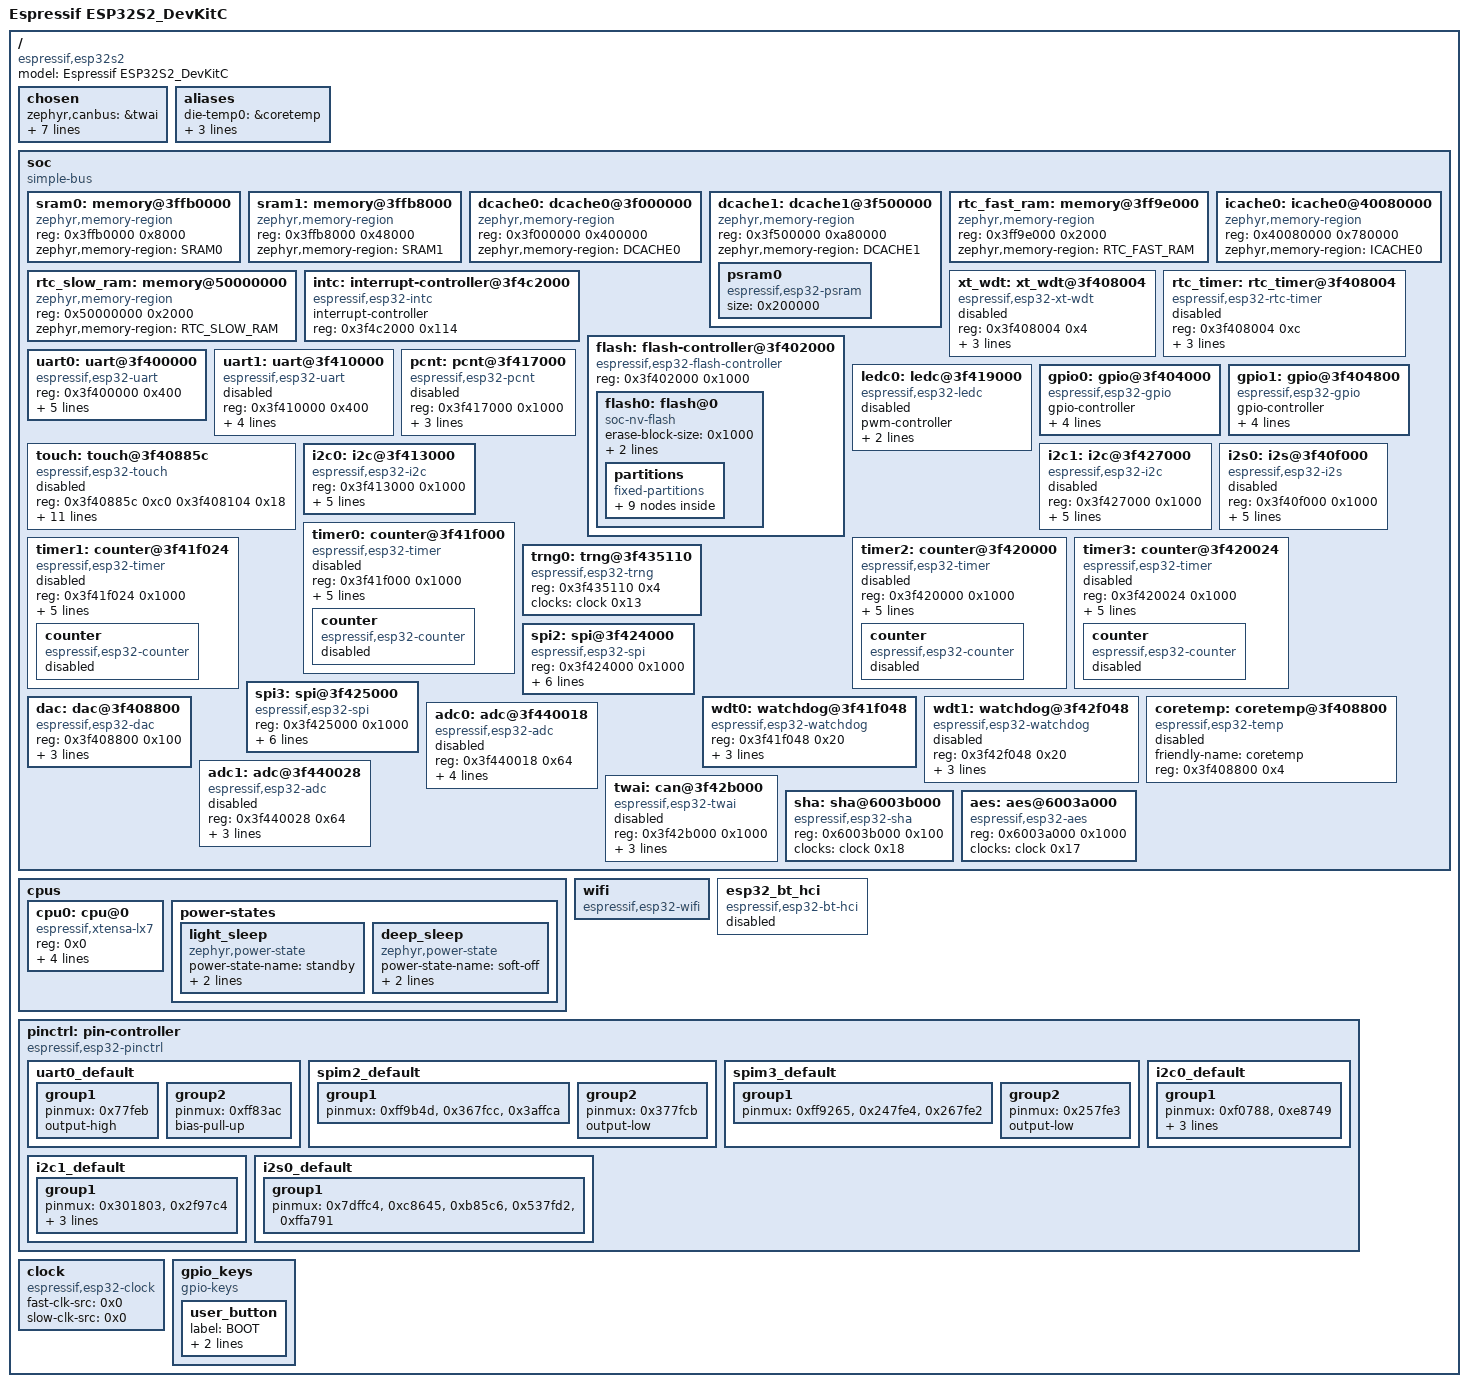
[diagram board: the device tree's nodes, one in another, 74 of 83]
/dts-v1/;

/* node '/' defined in zephyr/dts/common/skeleton.dtsi:9 */
/ {
	#address-cells = < 0x1 >;            /* in zephyr/dts/xtensa/espressif/esp32s2/esp32s2_common.dtsi:17 */
	#size-cells = < 0x1 >;               /* in zephyr/dts/xtensa/espressif/esp32s2/esp32s2_common.dtsi:18 */
	model = "Espressif ESP32S2_DevKitC"; /* in zephyr/boards/espressif/esp32s2_devkitc/esp32s2_devkitc.dts:16 */
	compatible = "espressif,esp32s2";    /* in zephyr/boards/espressif/esp32s2_devkitc/esp32s2_devkitc.dts:17 */

	/* node '/chosen' defined in zephyr/dts/common/skeleton.dtsi:13 */
	chosen {
		zephyr,canbus = &twai;                    /* in zephyr/dts/xtensa/espressif/esp32s2/esp32s2_common.dtsi:25 */
		zephyr,entropy = &trng0;                  /* in zephyr/dts/xtensa/espressif/esp32s2/esp32s2_common.dtsi:26 */
		zephyr,flash-controller = &flash;         /* in zephyr/dts/xtensa/espressif/esp32s2/esp32s2_common.dtsi:27 */
		zephyr,sram = &sram1;                     /* in zephyr/boards/espressif/esp32s2_devkitc/esp32s2_devkitc.dts:26 */
		zephyr,console = &uart0;                  /* in zephyr/boards/espressif/esp32s2_devkitc/esp32s2_devkitc.dts:27 */
		zephyr,shell-uart = &uart0;               /* in zephyr/boards/espressif/esp32s2_devkitc/esp32s2_devkitc.dts:28 */
		zephyr,flash = &flash0;                   /* in zephyr/boards/espressif/esp32s2_devkitc/esp32s2_devkitc.dts:29 */
		zephyr,code-partition = &slot0_partition; /* in zephyr/boards/espressif/esp32s2_devkitc/esp32s2_devkitc.dts:30 */
	};

	/* node '/aliases' defined in zephyr/dts/common/skeleton.dtsi:15 */
	aliases {
		die-temp0 = &coretemp; /* in zephyr/dts/xtensa/espressif/esp32s2/esp32s2_common.dtsi:21 */
		sw0 = &user_button;    /* in zephyr/boards/espressif/esp32s2_devkitc/esp32s2_devkitc.dts:20 */
		i2c-0 = &i2c0;         /* in zephyr/boards/espressif/esp32s2_devkitc/esp32s2_devkitc.dts:21 */
		watchdog0 = &wdt0;     /* in zephyr/boards/espressif/esp32s2_devkitc/esp32s2_devkitc.dts:22 */
	};

	/* node '/soc' defined in zephyr/dts/xtensa/xtensa.dtsi:10 */
	soc {
		#address-cells = < 0x1 >;  /* in zephyr/dts/xtensa/espressif/esp32s2/esp32s2_common.dtsi:85 */
		#size-cells = < 0x1 >;     /* in zephyr/dts/xtensa/espressif/esp32s2/esp32s2_common.dtsi:86 */
		compatible = "simple-bus"; /* in zephyr/dts/xtensa/espressif/esp32s2/esp32s2_common.dtsi:87 */
		ranges;                    /* in zephyr/dts/xtensa/espressif/esp32s2/esp32s2_common.dtsi:88 */

		/* node '/soc/memory@3ffb0000' defined in zephyr/dts/xtensa/espressif/esp32s2/esp32s2_common.dtsi:90 */
		sram0: memory@3ffb0000 {
			compatible = "zephyr,memory-region",
			             "mmio-sram";            /* in zephyr/dts/xtensa/espressif/esp32s2/esp32s2_common.dtsi:91 */
			reg = < 0x3ffb0000 0x8000 >;         /* in zephyr/dts/xtensa/espressif/esp32s2/esp32s2_common.dtsi:92 */
			zephyr,memory-region = "SRAM0";      /* in zephyr/dts/xtensa/espressif/esp32s2/esp32s2_common.dtsi:93 */
		};

		/* node '/soc/memory@3ffb8000' defined in zephyr/dts/xtensa/espressif/esp32s2/esp32s2_common.dtsi:96 */
		sram1: memory@3ffb8000 {
			compatible = "zephyr,memory-region",
			             "mmio-sram";            /* in zephyr/dts/xtensa/espressif/esp32s2/esp32s2_common.dtsi:97 */
			reg = < 0x3ffb8000 0x48000 >;        /* in zephyr/dts/xtensa/espressif/esp32s2/esp32s2_common.dtsi:98 */
			zephyr,memory-region = "SRAM1";      /* in zephyr/dts/xtensa/espressif/esp32s2/esp32s2_common.dtsi:99 */
		};

		/* node '/soc/dcache0@3f000000' defined in zephyr/dts/xtensa/espressif/esp32s2/esp32s2_common.dtsi:102 */
		dcache0: dcache0@3f000000 {
			compatible = "zephyr,memory-region"; /* in zephyr/dts/xtensa/espressif/esp32s2/esp32s2_common.dtsi:103 */
			reg = < 0x3f000000 0x400000 >;       /* in zephyr/dts/xtensa/espressif/esp32s2/esp32s2_common.dtsi:104 */
			zephyr,memory-region = "DCACHE0";    /* in zephyr/dts/xtensa/espressif/esp32s2/esp32s2_common.dtsi:105 */
		};

		/* node '/soc/dcache1@3f500000' defined in zephyr/dts/xtensa/espressif/esp32s2/esp32s2_common.dtsi:108 */
		dcache1: dcache1@3f500000 {
			compatible = "zephyr,memory-region"; /* in zephyr/dts/xtensa/espressif/esp32s2/esp32s2_common.dtsi:109 */
			reg = < 0x3f500000 0xa80000 >;       /* in zephyr/dts/xtensa/espressif/esp32s2/esp32s2_common.dtsi:110 */
			zephyr,memory-region = "DCACHE1";    /* in zephyr/dts/xtensa/espressif/esp32s2/esp32s2_common.dtsi:111 */

			/* node '/soc/dcache1@3f500000/psram0' defined in zephyr/dts/xtensa/espressif/esp32s2/esp32s2_common.dtsi:113 */
			psram0: psram0 {
				compatible = "espressif,esp32-psram"; /* in zephyr/dts/xtensa/espressif/esp32s2/esp32s2_common.dtsi:114 */
				size = < 0x200000 >;                  /* in zephyr/dts/xtensa/espressif/esp32s2/esp32s2_solo_n4r2.dtsi:16 */
			};
		};

		/* node '/soc/memory@3ff9e000' defined in zephyr/dts/xtensa/espressif/esp32s2/esp32s2_common.dtsi:119 */
		rtc_fast_ram: memory@3ff9e000 {
			compatible = "zephyr,memory-region",
			             "mmio-sram";              /* in zephyr/dts/xtensa/espressif/esp32s2/esp32s2_common.dtsi:120 */
			reg = < 0x3ff9e000 0x2000 >;           /* in zephyr/dts/xtensa/espressif/esp32s2/esp32s2_common.dtsi:121 */
			zephyr,memory-region = "RTC_FAST_RAM"; /* in zephyr/dts/xtensa/espressif/esp32s2/esp32s2_common.dtsi:122 */
		};

		/* node '/soc/memory@50000000' defined in zephyr/dts/xtensa/espressif/esp32s2/esp32s2_common.dtsi:125 */
		rtc_slow_ram: memory@50000000 {
			compatible = "zephyr,memory-region",
			             "mmio-sram";              /* in zephyr/dts/xtensa/espressif/esp32s2/esp32s2_common.dtsi:126 */
			reg = < 0x50000000 0x2000 >;           /* in zephyr/dts/xtensa/espressif/esp32s2/esp32s2_common.dtsi:127 */
			zephyr,memory-region = "RTC_SLOW_RAM"; /* in zephyr/dts/xtensa/espressif/esp32s2/esp32s2_common.dtsi:128 */
		};

		/* node '/soc/icache0@40080000' defined in zephyr/dts/xtensa/espressif/esp32s2/esp32s2_common.dtsi:131 */
		icache0: icache0@40080000 {
			compatible = "zephyr,memory-region"; /* in zephyr/dts/xtensa/espressif/esp32s2/esp32s2_common.dtsi:132 */
			reg = < 0x40080000 0x780000 >;       /* in zephyr/dts/xtensa/espressif/esp32s2/esp32s2_common.dtsi:133 */
			zephyr,memory-region = "ICACHE0";    /* in zephyr/dts/xtensa/espressif/esp32s2/esp32s2_common.dtsi:134 */
		};

		/* node '/soc/interrupt-controller@3f4c2000' defined in zephyr/dts/xtensa/espressif/esp32s2/esp32s2_common.dtsi:137 */
		intc: interrupt-controller@3f4c2000 {
			#interrupt-cells = < 0x3 >;          /* in zephyr/dts/xtensa/espressif/esp32s2/esp32s2_common.dtsi:138 */
			#address-cells = < 0x0 >;            /* in zephyr/dts/xtensa/espressif/esp32s2/esp32s2_common.dtsi:139 */
			compatible = "espressif,esp32-intc"; /* in zephyr/dts/xtensa/espressif/esp32s2/esp32s2_common.dtsi:140 */
			interrupt-controller;                /* in zephyr/dts/xtensa/espressif/esp32s2/esp32s2_common.dtsi:141 */
			reg = < 0x3f4c2000 0x114 >;          /* in zephyr/dts/xtensa/espressif/esp32s2/esp32s2_common.dtsi:142 */
			status = "okay";                     /* in zephyr/dts/xtensa/espressif/esp32s2/esp32s2_common.dtsi:143 */
			phandle = < 0x2 >;                   /* in zephyr/dts/xtensa/espressif/esp32s2/esp32s2_common.dtsi:151 */
		};

		/* node '/soc/xt_wdt@3f408004' defined in zephyr/dts/xtensa/espressif/esp32s2/esp32s2_common.dtsi:146 */
		xt_wdt: xt_wdt@3f408004 {
			compatible = "espressif,esp32-xt-wdt"; /* in zephyr/dts/xtensa/espressif/esp32s2/esp32s2_common.dtsi:147 */
			reg = < 0x3f408004 0x4 >;              /* in zephyr/dts/xtensa/espressif/esp32s2/esp32s2_common.dtsi:148 */
			clocks = < &clock 0x1f >;              /* in zephyr/dts/xtensa/espressif/esp32s2/esp32s2_common.dtsi:149 */
			interrupts = < 0x31 0x0 0x0 >;         /* in zephyr/dts/xtensa/espressif/esp32s2/esp32s2_common.dtsi:150 */
			interrupt-parent = < &intc >;          /* in zephyr/dts/xtensa/espressif/esp32s2/esp32s2_common.dtsi:151 */
			status = "disabled";                   /* in zephyr/dts/xtensa/espressif/esp32s2/esp32s2_common.dtsi:152 */
		};

		/* node '/soc/rtc_timer@3f408004' defined in zephyr/dts/xtensa/espressif/esp32s2/esp32s2_common.dtsi:155 */
		rtc_timer: rtc_timer@3f408004 {
			reg = < 0x3f408004 0xc >;                 /* in zephyr/dts/xtensa/espressif/esp32s2/esp32s2_common.dtsi:156 */
			compatible = "espressif,esp32-rtc-timer"; /* in zephyr/dts/xtensa/espressif/esp32s2/esp32s2_common.dtsi:157 */
			clocks = < &clock 0x1f >;                 /* in zephyr/dts/xtensa/espressif/esp32s2/esp32s2_common.dtsi:158 */
			interrupts = < 0x31 0x0 0x0 >;            /* in zephyr/dts/xtensa/espressif/esp32s2/esp32s2_common.dtsi:159 */
			interrupt-parent = < &intc >;             /* in zephyr/dts/xtensa/espressif/esp32s2/esp32s2_common.dtsi:160 */
			status = "disabled";                      /* in zephyr/dts/xtensa/espressif/esp32s2/esp32s2_common.dtsi:161 */
		};

		/* node '/soc/flash-controller@3f402000' defined in zephyr/dts/xtensa/espressif/esp32s2/esp32s2_common.dtsi:164 */
		flash: flash-controller@3f402000 {
			compatible = "espressif,esp32-flash-controller"; /* in zephyr/dts/xtensa/espressif/esp32s2/esp32s2_common.dtsi:165 */
			reg = < 0x3f402000 0x1000 >;                     /* in zephyr/dts/xtensa/espressif/esp32s2/esp32s2_common.dtsi:166 */
			#address-cells = < 0x1 >;                        /* in zephyr/dts/xtensa/espressif/esp32s2/esp32s2_common.dtsi:168 */
			#size-cells = < 0x1 >;                           /* in zephyr/dts/xtensa/espressif/esp32s2/esp32s2_common.dtsi:169 */

			/* node '/soc/flash-controller@3f402000/flash@0' defined in zephyr/dts/xtensa/espressif/esp32s2/esp32s2_common.dtsi:171 */
			flash0: flash@0 {
				compatible = "soc-nv-flash";   /* in zephyr/dts/xtensa/espressif/esp32s2/esp32s2_common.dtsi:172 */
				erase-block-size = < 0x1000 >; /* in zephyr/dts/xtensa/espressif/esp32s2/esp32s2_common.dtsi:173 */
				write-block-size = < 0x4 >;    /* in zephyr/dts/xtensa/espressif/esp32s2/esp32s2_common.dtsi:174 */
				reg = < 0x0 0x400000 >;        /* in zephyr/dts/xtensa/espressif/esp32s2/esp32s2_solo_n4r2.dtsi:11 */

				/* node '/soc/flash-controller@3f402000/flash@0/partitions' defined in zephyr/dts/vendor/espressif/partitions_0x1000_default_4M.dtsi:8 */
				partitions {
					compatible = "fixed-partitions"; /* in zephyr/dts/vendor/espressif/partitions_0x1000_default_4M.dtsi:9 */
					#address-cells = < 0x1 >;        /* in zephyr/dts/vendor/espressif/partitions_0x1000_default_4M.dtsi:10 */
					#size-cells = < 0x1 >;           /* in zephyr/dts/vendor/espressif/partitions_0x1000_default_4M.dtsi:11 */

					/* node '/soc/flash-controller@3f402000/flash@0/partitions/partition@1000' defined in zephyr/dts/vendor/espressif/partitions_0x1000_default_4M.dtsi:13 */
					boot_partition: partition@1000 {
						label = "mcuboot";       /* in zephyr/dts/vendor/espressif/partitions_0x1000_default_4M.dtsi:14 */
						reg = < 0x1000 0xf000 >; /* in zephyr/dts/vendor/espressif/partitions_0x1000_default_4M.dtsi:15 */
					};

					/* node '/soc/flash-controller@3f402000/flash@0/partitions/partition@10000' defined in zephyr/dts/vendor/espressif/partitions_0x1000_default_4M.dtsi:18 */
					sys_partition: partition@10000 {
						label = "sys";             /* in zephyr/dts/vendor/espressif/partitions_0x1000_default_4M.dtsi:19 */
						reg = < 0x10000 0x10000 >; /* in zephyr/dts/vendor/espressif/partitions_0x1000_default_4M.dtsi:20 */
					};

					/* node '/soc/flash-controller@3f402000/flash@0/partitions/partition@20000' defined in zephyr/dts/vendor/espressif/partitions_0x1000_default_4M.dtsi:23 */
					slot0_partition: partition@20000 {
						label = "image-0";          /* in zephyr/dts/vendor/espressif/partitions_0x1000_default_4M.dtsi:24 */
						reg = < 0x20000 0x1c0000 >; /* in zephyr/dts/vendor/espressif/partitions_0x1000_default_4M.dtsi:25 */
					};

					/* node '/soc/flash-controller@3f402000/flash@0/partitions/partition@1e0000' defined in zephyr/dts/vendor/espressif/partitions_0x1000_default_4M.dtsi:28 */
					slot1_partition: partition@1e0000 {
						label = "image-1";           /* in zephyr/dts/vendor/espressif/partitions_0x1000_default_4M.dtsi:29 */
						reg = < 0x1e0000 0x1c0000 >; /* in zephyr/dts/vendor/espressif/partitions_0x1000_default_4M.dtsi:30 */
					};

					/* node '/soc/flash-controller@3f402000/flash@0/partitions/partition@3a0000' defined in zephyr/dts/vendor/espressif/partitions_0x1000_default_4M.dtsi:33 */
					slot0_lpcore_partition: partition@3a0000 {
						label = "image-0-lpcore";  /* in zephyr/dts/vendor/espressif/partitions_0x1000_default_4M.dtsi:34 */
						reg = < 0x3a0000 0x8000 >; /* in zephyr/dts/vendor/espressif/partitions_0x1000_default_4M.dtsi:35 */
					};

					/* node '/soc/flash-controller@3f402000/flash@0/partitions/partition@3a8000' defined in zephyr/dts/vendor/espressif/partitions_0x1000_default_4M.dtsi:38 */
					slot1_lpcore_partition: partition@3a8000 {
						label = "image-1-lpcore";  /* in zephyr/dts/vendor/espressif/partitions_0x1000_default_4M.dtsi:39 */
						reg = < 0x3a8000 0x8000 >; /* in zephyr/dts/vendor/espressif/partitions_0x1000_default_4M.dtsi:40 */
					};

					/* node '/soc/flash-controller@3f402000/flash@0/partitions/partition@3b0000' defined in zephyr/dts/vendor/espressif/partitions_0x1000_default_4M.dtsi:43 */
					storage_partition: partition@3b0000 {
						label = "storage";          /* in zephyr/dts/vendor/espressif/partitions_0x1000_default_4M.dtsi:44 */
						reg = < 0x3b0000 0x30000 >; /* in zephyr/dts/vendor/espressif/partitions_0x1000_default_4M.dtsi:45 */
					};

					/* node '/soc/flash-controller@3f402000/flash@0/partitions/partition@3e0000' defined in zephyr/dts/vendor/espressif/partitions_0x1000_default_4M.dtsi:48 */
					scratch_partition: partition@3e0000 {
						label = "image-scratch";    /* in zephyr/dts/vendor/espressif/partitions_0x1000_default_4M.dtsi:49 */
						reg = < 0x3e0000 0x1f000 >; /* in zephyr/dts/vendor/espressif/partitions_0x1000_default_4M.dtsi:50 */
					};

					/* node '/soc/flash-controller@3f402000/flash@0/partitions/partition@3ff000' defined in zephyr/dts/vendor/espressif/partitions_0x1000_default_4M.dtsi:53 */
					coredump_partition: partition@3ff000 {
						label = "coredump";        /* in zephyr/dts/vendor/espressif/partitions_0x1000_default_4M.dtsi:54 */
						reg = < 0x3ff000 0x1000 >; /* in zephyr/dts/vendor/espressif/partitions_0x1000_default_4M.dtsi:55 */
					};
				};
			};
		};

		/* node '/soc/uart@3f400000' defined in zephyr/dts/xtensa/espressif/esp32s2/esp32s2_common.dtsi:179 */
		uart0: uart@3f400000 {
			compatible = "espressif,esp32-uart"; /* in zephyr/dts/xtensa/espressif/esp32s2/esp32s2_common.dtsi:180 */
			reg = < 0x3f400000 0x400 >;          /* in zephyr/dts/xtensa/espressif/esp32s2/esp32s2_common.dtsi:181 */
			interrupts = < 0x25 0x0 0x0 >;       /* in zephyr/dts/xtensa/espressif/esp32s2/esp32s2_common.dtsi:183 */
			interrupt-parent = < &intc >;        /* in zephyr/dts/xtensa/espressif/esp32s2/esp32s2_common.dtsi:184 */
			clocks = < &clock 0x1 >;             /* in zephyr/dts/xtensa/espressif/esp32s2/esp32s2_common.dtsi:185 */
			status = "okay";                     /* in zephyr/boards/espressif/esp32s2_devkitc/esp32s2_devkitc.dts:45 */
			current-speed = < 0x1c200 >;         /* in zephyr/boards/espressif/esp32s2_devkitc/esp32s2_devkitc.dts:46 */
			pinctrl-0 = < &uart0_default >;      /* in zephyr/boards/espressif/esp32s2_devkitc/esp32s2_devkitc.dts:47 */
			pinctrl-names = "default";           /* in zephyr/boards/espressif/esp32s2_devkitc/esp32s2_devkitc.dts:48 */
		};

		/* node '/soc/uart@3f410000' defined in zephyr/dts/xtensa/espressif/esp32s2/esp32s2_common.dtsi:188 */
		uart1: uart@3f410000 {
			compatible = "espressif,esp32-uart"; /* in zephyr/dts/xtensa/espressif/esp32s2/esp32s2_common.dtsi:189 */
			reg = < 0x3f410000 0x400 >;          /* in zephyr/dts/xtensa/espressif/esp32s2/esp32s2_common.dtsi:190 */
			status = "disabled";                 /* in zephyr/dts/xtensa/espressif/esp32s2/esp32s2_common.dtsi:191 */
			interrupts = < 0x26 0x0 0x0 >;       /* in zephyr/dts/xtensa/espressif/esp32s2/esp32s2_common.dtsi:192 */
			interrupt-parent = < &intc >;        /* in zephyr/dts/xtensa/espressif/esp32s2/esp32s2_common.dtsi:193 */
			clocks = < &clock 0x2 >;             /* in zephyr/dts/xtensa/espressif/esp32s2/esp32s2_common.dtsi:194 */
			current-speed = < 0x1c200 >;         /* in zephyr/dts/xtensa/espressif/esp32s2/esp32s2_common.dtsi:195 */
		};

		/* node '/soc/pcnt@3f417000' defined in zephyr/dts/xtensa/espressif/esp32s2/esp32s2_common.dtsi:198 */
		pcnt: pcnt@3f417000 {
			compatible = "espressif,esp32-pcnt"; /* in zephyr/dts/xtensa/espressif/esp32s2/esp32s2_common.dtsi:199 */
			reg = < 0x3f417000 0x1000 >;         /* in zephyr/dts/xtensa/espressif/esp32s2/esp32s2_common.dtsi:200 */
			interrupts = < 0x33 0x0 0x0 >;       /* in zephyr/dts/xtensa/espressif/esp32s2/esp32s2_common.dtsi:201 */
			interrupt-parent = < &intc >;        /* in zephyr/dts/xtensa/espressif/esp32s2/esp32s2_common.dtsi:202 */
			clocks = < &clock 0xc >;             /* in zephyr/dts/xtensa/espressif/esp32s2/esp32s2_common.dtsi:203 */
			status = "disabled";                 /* in zephyr/dts/xtensa/espressif/esp32s2/esp32s2_common.dtsi:204 */
		};

		/* node '/soc/ledc@3f419000' defined in zephyr/dts/xtensa/espressif/esp32s2/esp32s2_common.dtsi:207 */
		ledc0: ledc@3f419000 {
			compatible = "espressif,esp32-ledc"; /* in zephyr/dts/xtensa/espressif/esp32s2/esp32s2_common.dtsi:208 */
			pwm-controller;                      /* in zephyr/dts/xtensa/espressif/esp32s2/esp32s2_common.dtsi:209 */
			#pwm-cells = < 0x3 >;                /* in zephyr/dts/xtensa/espressif/esp32s2/esp32s2_common.dtsi:210 */
			reg = < 0x3f419000 0x1000 >;         /* in zephyr/dts/xtensa/espressif/esp32s2/esp32s2_common.dtsi:211 */
			clocks = < &clock 0x0 >;             /* in zephyr/dts/xtensa/espressif/esp32s2/esp32s2_common.dtsi:212 */
			status = "disabled";                 /* in zephyr/dts/xtensa/espressif/esp32s2/esp32s2_common.dtsi:213 */
		};

		/* node '/soc/gpio@3f404000' defined in zephyr/dts/xtensa/espressif/esp32s2/esp32s2_common.dtsi:216 */
		gpio0: gpio@3f404000 {
			compatible = "espressif,esp32-gpio"; /* in zephyr/dts/xtensa/espressif/esp32s2/esp32s2_common.dtsi:217 */
			gpio-controller;                     /* in zephyr/dts/xtensa/espressif/esp32s2/esp32s2_common.dtsi:218 */
			#gpio-cells = < 0x2 >;               /* in zephyr/dts/xtensa/espressif/esp32s2/esp32s2_common.dtsi:219 */
			reg = < 0x3f404000 0x800 >;          /* in zephyr/dts/xtensa/espressif/esp32s2/esp32s2_common.dtsi:220 */
			interrupts = < 0x17 0x0 0x0 >;       /* in zephyr/dts/xtensa/espressif/esp32s2/esp32s2_common.dtsi:221 */
			interrupt-parent = < &intc >;        /* in zephyr/dts/xtensa/espressif/esp32s2/esp32s2_common.dtsi:222 */
			ngpios = < 0x20 >;                   /* in zephyr/dts/xtensa/espressif/esp32s2/esp32s2_common.dtsi:228 */
			status = "okay";                     /* in zephyr/boards/espressif/esp32s2_devkitc/esp32s2_devkitc.dts:52 */
			phandle = < 0xb >;                   /* in zephyr/boards/espressif/esp32s2_devkitc/esp32s2_devkitc.dts:38 */
		};

		/* node '/soc/gpio@3f404800' defined in zephyr/dts/xtensa/espressif/esp32s2/esp32s2_common.dtsi:231 */
		gpio1: gpio@3f404800 {
			compatible = "espressif,esp32-gpio"; /* in zephyr/dts/xtensa/espressif/esp32s2/esp32s2_common.dtsi:232 */
			gpio-controller;                     /* in zephyr/dts/xtensa/espressif/esp32s2/esp32s2_common.dtsi:233 */
			#gpio-cells = < 0x2 >;               /* in zephyr/dts/xtensa/espressif/esp32s2/esp32s2_common.dtsi:234 */
			reg = < 0x3f404800 0x800 >;          /* in zephyr/dts/xtensa/espressif/esp32s2/esp32s2_common.dtsi:235 */
			interrupts = < 0x17 0x0 0x0 >;       /* in zephyr/dts/xtensa/espressif/esp32s2/esp32s2_common.dtsi:236 */
			interrupt-parent = < &intc >;        /* in zephyr/dts/xtensa/espressif/esp32s2/esp32s2_common.dtsi:237 */
			ngpios = < 0x16 >;                   /* in zephyr/dts/xtensa/espressif/esp32s2/esp32s2_common.dtsi:238 */
			status = "okay";                     /* in zephyr/boards/espressif/esp32s2_devkitc/esp32s2_devkitc.dts:56 */
		};

		/* node '/soc/touch@3f40885c' defined in zephyr/dts/xtensa/espressif/esp32s2/esp32s2_common.dtsi:241 */
		touch: touch@3f40885c {
			compatible = "espressif,esp32-touch";      /* in zephyr/dts/xtensa/espressif/esp32s2/esp32s2_common.dtsi:242 */
			reg = < 0x3f40885c 0xc0 0x3f408104 0x18 >; /* in zephyr/dts/xtensa/espressif/esp32s2/esp32s2_common.dtsi:243 */
			interrupts = < 0x31 0x0 0x0 >;             /* in zephyr/dts/xtensa/espressif/esp32s2/esp32s2_common.dtsi:244 */
			interrupt-parent = < &intc >;              /* in zephyr/dts/xtensa/espressif/esp32s2/esp32s2_common.dtsi:245 */
			status = "disabled";                       /* in zephyr/dts/xtensa/espressif/esp32s2/esp32s2_common.dtsi:246 */
			debounce-interval-ms = < 0x1e >;           /* in zephyr/boards/espressif/esp32s2_devkitc/esp32s2_devkitc.dts:60 */
			href-microvolt = < 0x2932e0 >;             /* in zephyr/boards/espressif/esp32s2_devkitc/esp32s2_devkitc.dts:61 */
			lref-microvolt = < 0x7a120 >;              /* in zephyr/boards/espressif/esp32s2_devkitc/esp32s2_devkitc.dts:62 */
			href-atten-microvolt = < 0xf4240 >;        /* in zephyr/boards/espressif/esp32s2_devkitc/esp32s2_devkitc.dts:63 */
			filter-mode = < 0x2 >;                     /* in zephyr/boards/espressif/esp32s2_devkitc/esp32s2_devkitc.dts:64 */
			filter-debounce-cnt = < 0x1 >;             /* in zephyr/boards/espressif/esp32s2_devkitc/esp32s2_devkitc.dts:65 */
			filter-noise-thr = < 0x0 >;                /* in zephyr/boards/espressif/esp32s2_devkitc/esp32s2_devkitc.dts:66 */
			filter-jitter-step = < 0x4 >;              /* in zephyr/boards/espressif/esp32s2_devkitc/esp32s2_devkitc.dts:67 */
			filter-smooth-level = < 0x1 >;             /* in zephyr/boards/espressif/esp32s2_devkitc/esp32s2_devkitc.dts:68 */
		};

		/* node '/soc/i2c@3f413000' defined in zephyr/dts/xtensa/espressif/esp32s2/esp32s2_common.dtsi:249 */
		i2c0: i2c@3f413000 {
			compatible = "espressif,esp32-i2c"; /* in zephyr/dts/xtensa/espressif/esp32s2/esp32s2_common.dtsi:250 */
			#address-cells = < 0x1 >;           /* in zephyr/dts/xtensa/espressif/esp32s2/esp32s2_common.dtsi:251 */
			#size-cells = < 0x0 >;              /* in zephyr/dts/xtensa/espressif/esp32s2/esp32s2_common.dtsi:252 */
			reg = < 0x3f413000 0x1000 >;        /* in zephyr/dts/xtensa/espressif/esp32s2/esp32s2_common.dtsi:253 */
			interrupts = < 0x34 0x0 0x0 >;      /* in zephyr/dts/xtensa/espressif/esp32s2/esp32s2_common.dtsi:254 */
			interrupt-parent = < &intc >;       /* in zephyr/dts/xtensa/espressif/esp32s2/esp32s2_common.dtsi:255 */
			clocks = < &clock 0x4 >;            /* in zephyr/dts/xtensa/espressif/esp32s2/esp32s2_common.dtsi:256 */
			status = "okay";                    /* in zephyr/boards/espressif/esp32s2_devkitc/esp32s2_devkitc.dts:88 */
			clock-frequency = < 0x186a0 >;      /* in zephyr/boards/espressif/esp32s2_devkitc/esp32s2_devkitc.dts:89 */
			pinctrl-0 = < &i2c0_default >;      /* in zephyr/boards/espressif/esp32s2_devkitc/esp32s2_devkitc.dts:90 */
			pinctrl-names = "default";          /* in zephyr/boards/espressif/esp32s2_devkitc/esp32s2_devkitc.dts:91 */
		};

		/* node '/soc/i2c@3f427000' defined in zephyr/dts/xtensa/espressif/esp32s2/esp32s2_common.dtsi:260 */
		i2c1: i2c@3f427000 {
			compatible = "espressif,esp32-i2c"; /* in zephyr/dts/xtensa/espressif/esp32s2/esp32s2_common.dtsi:261 */
			#address-cells = < 0x1 >;           /* in zephyr/dts/xtensa/espressif/esp32s2/esp32s2_common.dtsi:262 */
			#size-cells = < 0x0 >;              /* in zephyr/dts/xtensa/espressif/esp32s2/esp32s2_common.dtsi:263 */
			reg = < 0x3f427000 0x1000 >;        /* in zephyr/dts/xtensa/espressif/esp32s2/esp32s2_common.dtsi:264 */
			interrupts = < 0x35 0x0 0x0 >;      /* in zephyr/dts/xtensa/espressif/esp32s2/esp32s2_common.dtsi:265 */
			interrupt-parent = < &intc >;       /* in zephyr/dts/xtensa/espressif/esp32s2/esp32s2_common.dtsi:266 */
			clocks = < &clock 0x5 >;            /* in zephyr/dts/xtensa/espressif/esp32s2/esp32s2_common.dtsi:267 */
			status = "disabled";                /* in zephyr/dts/xtensa/espressif/esp32s2/esp32s2_common.dtsi:268 */
			clock-frequency = < 0x186a0 >;      /* in zephyr/boards/espressif/esp32s2_devkitc/esp32s2_devkitc.dts:95 */
			pinctrl-0 = < &i2c1_default >;      /* in zephyr/boards/espressif/esp32s2_devkitc/esp32s2_devkitc.dts:96 */
			pinctrl-names = "default";          /* in zephyr/boards/espressif/esp32s2_devkitc/esp32s2_devkitc.dts:97 */
		};

		/* node '/soc/i2s@3f40f000' defined in zephyr/dts/xtensa/espressif/esp32s2/esp32s2_common.dtsi:271 */
		i2s0: i2s@3f40f000 {
			compatible = "espressif,esp32-i2s"; /* in zephyr/dts/xtensa/espressif/esp32s2/esp32s2_common.dtsi:272 */
			#address-cells = < 0x1 >;           /* in zephyr/dts/xtensa/espressif/esp32s2/esp32s2_common.dtsi:273 */
			#size-cells = < 0x0 >;              /* in zephyr/dts/xtensa/espressif/esp32s2/esp32s2_common.dtsi:274 */
			reg = < 0x3f40f000 0x1000 >;        /* in zephyr/dts/xtensa/espressif/esp32s2/esp32s2_common.dtsi:275 */
			interrupts = < 0x23 0x0 0x0 >,
			             < 0x23 0x0 0x0 >;      /* in zephyr/dts/xtensa/espressif/esp32s2/esp32s2_common.dtsi:276 */
			interrupt-names = "rx",
			                  "tx";             /* in zephyr/dts/xtensa/espressif/esp32s2/esp32s2_common.dtsi:278 */
			interrupt-parent = < &intc >;       /* in zephyr/dts/xtensa/espressif/esp32s2/esp32s2_common.dtsi:279 */
			clocks = < &clock 0x6 >;            /* in zephyr/dts/xtensa/espressif/esp32s2/esp32s2_common.dtsi:280 */
			unit = < 0x0 >;                     /* in zephyr/dts/xtensa/espressif/esp32s2/esp32s2_common.dtsi:281 */
			status = "disabled";                /* in zephyr/dts/xtensa/espressif/esp32s2/esp32s2_common.dtsi:282 */
			pinctrl-0 = < &i2s0_default >;      /* in zephyr/boards/espressif/esp32s2_devkitc/esp32s2_devkitc.dts:101 */
			pinctrl-names = "default";          /* in zephyr/boards/espressif/esp32s2_devkitc/esp32s2_devkitc.dts:102 */
		};

		/* node '/soc/counter@3f41f000' defined in zephyr/dts/xtensa/espressif/esp32s2/esp32s2_common.dtsi:285 */
		timer0: counter@3f41f000 {
			compatible = "espressif,esp32-timer"; /* in zephyr/dts/xtensa/espressif/esp32s2/esp32s2_common.dtsi:286 */
			reg = < 0x3f41f000 0x1000 >;          /* in zephyr/dts/xtensa/espressif/esp32s2/esp32s2_common.dtsi:287 */
			clocks = < &clock 0x7 >;              /* in zephyr/dts/xtensa/espressif/esp32s2/esp32s2_common.dtsi:288 */
			group = < 0x0 >;                      /* in zephyr/dts/xtensa/espressif/esp32s2/esp32s2_common.dtsi:289 */
			index = < 0x0 >;                      /* in zephyr/dts/xtensa/espressif/esp32s2/esp32s2_common.dtsi:290 */
			interrupts = < 0xf 0x0 0x0 >;         /* in zephyr/dts/xtensa/espressif/esp32s2/esp32s2_common.dtsi:291 */
			interrupt-parent = < &intc >;         /* in zephyr/dts/xtensa/espressif/esp32s2/esp32s2_common.dtsi:292 */
			status = "disabled";                  /* in zephyr/boards/espressif/esp32s2_devkitc/esp32s2_devkitc.dts:72 */

			/* node '/soc/counter@3f41f000/counter' defined in zephyr/dts/xtensa/espressif/esp32s2/esp32s2_common.dtsi:295 */
			counter {
				compatible = "espressif,esp32-counter"; /* in zephyr/dts/xtensa/espressif/esp32s2/esp32s2_common.dtsi:296 */
				status = "disabled";                    /* in zephyr/dts/xtensa/espressif/esp32s2/esp32s2_common.dtsi:297 */
			};
		};

		/* node '/soc/counter@3f41f024' defined in zephyr/dts/xtensa/espressif/esp32s2/esp32s2_common.dtsi:301 */
		timer1: counter@3f41f024 {
			compatible = "espressif,esp32-timer"; /* in zephyr/dts/xtensa/espressif/esp32s2/esp32s2_common.dtsi:302 */
			reg = < 0x3f41f024 0x1000 >;          /* in zephyr/dts/xtensa/espressif/esp32s2/esp32s2_common.dtsi:303 */
			clocks = < &clock 0x7 >;              /* in zephyr/dts/xtensa/espressif/esp32s2/esp32s2_common.dtsi:304 */
			group = < 0x0 >;                      /* in zephyr/dts/xtensa/espressif/esp32s2/esp32s2_common.dtsi:305 */
			index = < 0x1 >;                      /* in zephyr/dts/xtensa/espressif/esp32s2/esp32s2_common.dtsi:306 */
			interrupts = < 0x10 0x0 0x0 >;        /* in zephyr/dts/xtensa/espressif/esp32s2/esp32s2_common.dtsi:307 */
			interrupt-parent = < &intc >;         /* in zephyr/dts/xtensa/espressif/esp32s2/esp32s2_common.dtsi:308 */
			status = "disabled";                  /* in zephyr/boards/espressif/esp32s2_devkitc/esp32s2_devkitc.dts:76 */

			/* node '/soc/counter@3f41f024/counter' defined in zephyr/dts/xtensa/espressif/esp32s2/esp32s2_common.dtsi:311 */
			counter {
				compatible = "espressif,esp32-counter"; /* in zephyr/dts/xtensa/espressif/esp32s2/esp32s2_common.dtsi:312 */
				status = "disabled";                    /* in zephyr/dts/xtensa/espressif/esp32s2/esp32s2_common.dtsi:313 */
			};
		};

		/* node '/soc/counter@3f420000' defined in zephyr/dts/xtensa/espressif/esp32s2/esp32s2_common.dtsi:317 */
		timer2: counter@3f420000 {
			compatible = "espressif,esp32-timer"; /* in zephyr/dts/xtensa/espressif/esp32s2/esp32s2_common.dtsi:318 */
			reg = < 0x3f420000 0x1000 >;          /* in zephyr/dts/xtensa/espressif/esp32s2/esp32s2_common.dtsi:319 */
			clocks = < &clock 0x8 >;              /* in zephyr/dts/xtensa/espressif/esp32s2/esp32s2_common.dtsi:320 */
			group = < 0x1 >;                      /* in zephyr/dts/xtensa/espressif/esp32s2/esp32s2_common.dtsi:321 */
			index = < 0x0 >;                      /* in zephyr/dts/xtensa/espressif/esp32s2/esp32s2_common.dtsi:322 */
			interrupts = < 0x13 0x0 0x0 >;        /* in zephyr/dts/xtensa/espressif/esp32s2/esp32s2_common.dtsi:323 */
			interrupt-parent = < &intc >;         /* in zephyr/dts/xtensa/espressif/esp32s2/esp32s2_common.dtsi:324 */
			status = "disabled";                  /* in zephyr/boards/espressif/esp32s2_devkitc/esp32s2_devkitc.dts:80 */

			/* node '/soc/counter@3f420000/counter' defined in zephyr/dts/xtensa/espressif/esp32s2/esp32s2_common.dtsi:327 */
			counter {
				compatible = "espressif,esp32-counter"; /* in zephyr/dts/xtensa/espressif/esp32s2/esp32s2_common.dtsi:328 */
				status = "disabled";                    /* in zephyr/dts/xtensa/espressif/esp32s2/esp32s2_common.dtsi:329 */
			};
		};

		/* node '/soc/counter@3f420024' defined in zephyr/dts/xtensa/espressif/esp32s2/esp32s2_common.dtsi:333 */
		timer3: counter@3f420024 {
			compatible = "espressif,esp32-timer"; /* in zephyr/dts/xtensa/espressif/esp32s2/esp32s2_common.dtsi:334 */
			reg = < 0x3f420024 0x1000 >;          /* in zephyr/dts/xtensa/espressif/esp32s2/esp32s2_common.dtsi:335 */
			clocks = < &clock 0x8 >;              /* in zephyr/dts/xtensa/espressif/esp32s2/esp32s2_common.dtsi:336 */
			group = < 0x1 >;                      /* in zephyr/dts/xtensa/espressif/esp32s2/esp32s2_common.dtsi:337 */
			index = < 0x1 >;                      /* in zephyr/dts/xtensa/espressif/esp32s2/esp32s2_common.dtsi:338 */
			interrupts = < 0x14 0x0 0x0 >;        /* in zephyr/dts/xtensa/espressif/esp32s2/esp32s2_common.dtsi:339 */
			interrupt-parent = < &intc >;         /* in zephyr/dts/xtensa/espressif/esp32s2/esp32s2_common.dtsi:340 */
			status = "disabled";                  /* in zephyr/boards/espressif/esp32s2_devkitc/esp32s2_devkitc.dts:84 */

			/* node '/soc/counter@3f420024/counter' defined in zephyr/dts/xtensa/espressif/esp32s2/esp32s2_common.dtsi:342 */
			counter {
				compatible = "espressif,esp32-counter"; /* in zephyr/dts/xtensa/espressif/esp32s2/esp32s2_common.dtsi:343 */
				status = "disabled";                    /* in zephyr/dts/xtensa/espressif/esp32s2/esp32s2_common.dtsi:344 */
			};
		};

		/* node '/soc/trng@3f435110' defined in zephyr/dts/xtensa/espressif/esp32s2/esp32s2_common.dtsi:348 */
		trng0: trng@3f435110 {
			compatible = "espressif,esp32-trng"; /* in zephyr/dts/xtensa/espressif/esp32s2/esp32s2_common.dtsi:349 */
			reg = < 0x3f435110 0x4 >;            /* in zephyr/dts/xtensa/espressif/esp32s2/esp32s2_common.dtsi:350 */
			clocks = < &clock 0x13 >;            /* in zephyr/dts/xtensa/espressif/esp32s2/esp32s2_common.dtsi:351 */
			status = "okay";                     /* in zephyr/boards/espressif/esp32s2_devkitc/esp32s2_devkitc.dts:106 */
		};

		/* node '/soc/spi@3f424000' defined in zephyr/dts/xtensa/espressif/esp32s2/esp32s2_common.dtsi:355 */
		spi2: spi@3f424000 {
			compatible = "espressif,esp32-spi"; /* in zephyr/dts/xtensa/espressif/esp32s2/esp32s2_common.dtsi:356 */
			reg = < 0x3f424000 0x1000 >;        /* in zephyr/dts/xtensa/espressif/esp32s2/esp32s2_common.dtsi:357 */
			interrupts = < 0x21 0x0 0x0 >;      /* in zephyr/dts/xtensa/espressif/esp32s2/esp32s2_common.dtsi:358 */
			interrupt-parent = < &intc >;       /* in zephyr/dts/xtensa/espressif/esp32s2/esp32s2_common.dtsi:359 */
			clocks = < &clock 0xe >;            /* in zephyr/dts/xtensa/espressif/esp32s2/esp32s2_common.dtsi:360 */
			dma-clk = < 0x10 >;                 /* in zephyr/dts/xtensa/espressif/esp32s2/esp32s2_common.dtsi:361 */
			dma-host = < 0x0 >;                 /* in zephyr/dts/xtensa/espressif/esp32s2/esp32s2_common.dtsi:362 */
			#address-cells = < 0x1 >;           /* in zephyr/boards/espressif/esp32s2_devkitc/esp32s2_devkitc.dts:110 */
			#size-cells = < 0x0 >;              /* in zephyr/boards/espressif/esp32s2_devkitc/esp32s2_devkitc.dts:111 */
			status = "okay";                    /* in zephyr/boards/espressif/esp32s2_devkitc/esp32s2_devkitc.dts:112 */
			pinctrl-0 = < &spim2_default >;     /* in zephyr/boards/espressif/esp32s2_devkitc/esp32s2_devkitc.dts:113 */
			pinctrl-names = "default";          /* in zephyr/boards/espressif/esp32s2_devkitc/esp32s2_devkitc.dts:114 */
		};

		/* node '/soc/spi@3f425000' defined in zephyr/dts/xtensa/espressif/esp32s2/esp32s2_common.dtsi:366 */
		spi3: spi@3f425000 {
			compatible = "espressif,esp32-spi"; /* in zephyr/dts/xtensa/espressif/esp32s2/esp32s2_common.dtsi:367 */
			reg = < 0x3f425000 0x1000 >;        /* in zephyr/dts/xtensa/espressif/esp32s2/esp32s2_common.dtsi:368 */
			interrupts = < 0x22 0x0 0x0 >;      /* in zephyr/dts/xtensa/espressif/esp32s2/esp32s2_common.dtsi:369 */
			interrupt-parent = < &intc >;       /* in zephyr/dts/xtensa/espressif/esp32s2/esp32s2_common.dtsi:370 */
			clocks = < &clock 0xf >;            /* in zephyr/dts/xtensa/espressif/esp32s2/esp32s2_common.dtsi:371 */
			dma-clk = < 0x11 >;                 /* in zephyr/dts/xtensa/espressif/esp32s2/esp32s2_common.dtsi:372 */
			dma-host = < 0x1 >;                 /* in zephyr/dts/xtensa/espressif/esp32s2/esp32s2_common.dtsi:373 */
			#address-cells = < 0x1 >;           /* in zephyr/boards/espressif/esp32s2_devkitc/esp32s2_devkitc.dts:118 */
			#size-cells = < 0x0 >;              /* in zephyr/boards/espressif/esp32s2_devkitc/esp32s2_devkitc.dts:119 */
			status = "okay";                    /* in zephyr/boards/espressif/esp32s2_devkitc/esp32s2_devkitc.dts:120 */
			pinctrl-0 = < &spim3_default >;     /* in zephyr/boards/espressif/esp32s2_devkitc/esp32s2_devkitc.dts:121 */
			pinctrl-names = "default";          /* in zephyr/boards/espressif/esp32s2_devkitc/esp32s2_devkitc.dts:122 */
		};

		/* node '/soc/watchdog@3f41f048' defined in zephyr/dts/xtensa/espressif/esp32s2/esp32s2_common.dtsi:377 */
		wdt0: watchdog@3f41f048 {
			compatible = "espressif,esp32-watchdog"; /* in zephyr/dts/xtensa/espressif/esp32s2/esp32s2_common.dtsi:378 */
			reg = < 0x3f41f048 0x20 >;               /* in zephyr/dts/xtensa/espressif/esp32s2/esp32s2_common.dtsi:379 */
			interrupts = < 0x11 0x0 0x0 >;           /* in zephyr/dts/xtensa/espressif/esp32s2/esp32s2_common.dtsi:380 */
			interrupt-parent = < &intc >;            /* in zephyr/dts/xtensa/espressif/esp32s2/esp32s2_common.dtsi:381 */
			clocks = < &clock 0x7 >;                 /* in zephyr/dts/xtensa/espressif/esp32s2/esp32s2_common.dtsi:382 */
			status = "okay";                         /* in zephyr/boards/espressif/esp32s2_devkitc/esp32s2_devkitc.dts:126 */
		};

		/* node '/soc/watchdog@3f42f048' defined in zephyr/dts/xtensa/espressif/esp32s2/esp32s2_common.dtsi:386 */
		wdt1: watchdog@3f42f048 {
			compatible = "espressif,esp32-watchdog"; /* in zephyr/dts/xtensa/espressif/esp32s2/esp32s2_common.dtsi:387 */
			reg = < 0x3f42f048 0x20 >;               /* in zephyr/dts/xtensa/espressif/esp32s2/esp32s2_common.dtsi:388 */
			interrupts = < 0x15 0x0 0x0 >;           /* in zephyr/dts/xtensa/espressif/esp32s2/esp32s2_common.dtsi:389 */
			interrupt-parent = < &intc >;            /* in zephyr/dts/xtensa/espressif/esp32s2/esp32s2_common.dtsi:390 */
			clocks = < &clock 0x8 >;                 /* in zephyr/dts/xtensa/espressif/esp32s2/esp32s2_common.dtsi:391 */
			status = "disabled";                     /* in zephyr/dts/xtensa/espressif/esp32s2/esp32s2_common.dtsi:392 */
		};

		/* node '/soc/dac@3f408800' defined in zephyr/dts/xtensa/espressif/esp32s2/esp32s2_common.dtsi:395 */
		dac: dac@3f408800 {
			compatible = "espressif,esp32-dac"; /* in zephyr/dts/xtensa/espressif/esp32s2/esp32s2_common.dtsi:396 */
			reg = < 0x3f408800 0x100 >;         /* in zephyr/dts/xtensa/espressif/esp32s2/esp32s2_common.dtsi:397 */
			interrupts = < 0x31 0x0 0x0 >;      /* in zephyr/dts/xtensa/espressif/esp32s2/esp32s2_common.dtsi:398 */
			interrupt-parent = < &intc >;       /* in zephyr/dts/xtensa/espressif/esp32s2/esp32s2_common.dtsi:399 */
			clocks = < &clock 0x1e >;           /* in zephyr/dts/xtensa/espressif/esp32s2/esp32s2_common.dtsi:400 */
			#io-channel-cells = < 0x1 >;        /* in zephyr/dts/xtensa/espressif/esp32s2/esp32s2_common.dtsi:401 */
			status = "okay";                    /* in zephyr/boards/espressif/esp32s2_devkitc/esp32s2_devkitc.dts:130 */
		};

		/* node '/soc/coretemp@3f408800' defined in zephyr/dts/xtensa/espressif/esp32s2/esp32s2_common.dtsi:404 */
		coretemp: coretemp@3f408800 {
			compatible = "espressif,esp32-temp"; /* in zephyr/dts/xtensa/espressif/esp32s2/esp32s2_common.dtsi:405 */
			friendly-name = "coretemp";          /* in zephyr/dts/xtensa/espressif/esp32s2/esp32s2_common.dtsi:406 */
			reg = < 0x3f408800 0x4 >;            /* in zephyr/dts/xtensa/espressif/esp32s2/esp32s2_common.dtsi:407 */
			status = "disabled";                 /* in zephyr/dts/xtensa/espressif/esp32s2/esp32s2_common.dtsi:408 */
		};

		/* node '/soc/adc@3f440018' defined in zephyr/dts/xtensa/espressif/esp32s2/esp32s2_common.dtsi:411 */
		adc0: adc@3f440018 {
			compatible = "espressif,esp32-adc"; /* in zephyr/dts/xtensa/espressif/esp32s2/esp32s2_common.dtsi:412 */
			reg = < 0x3f440018 0x64 >;          /* in zephyr/dts/xtensa/espressif/esp32s2/esp32s2_common.dtsi:413 */
			clocks = < &clock 0x1e >;           /* in zephyr/dts/xtensa/espressif/esp32s2/esp32s2_common.dtsi:414 */
			interrupt-parent = < &intc >;       /* in zephyr/dts/xtensa/espressif/esp32s2/esp32s2_common.dtsi:415 */
			unit = < 0x1 >;                     /* in zephyr/dts/xtensa/espressif/esp32s2/esp32s2_common.dtsi:416 */
			channel-count = < 0xa >;            /* in zephyr/dts/xtensa/espressif/esp32s2/esp32s2_common.dtsi:417 */
			#io-channel-cells = < 0x1 >;        /* in zephyr/dts/xtensa/espressif/esp32s2/esp32s2_common.dtsi:418 */
			status = "disabled";                /* in zephyr/dts/xtensa/espressif/esp32s2/esp32s2_common.dtsi:419 */
		};

		/* node '/soc/adc@3f440028' defined in zephyr/dts/xtensa/espressif/esp32s2/esp32s2_common.dtsi:422 */
		adc1: adc@3f440028 {
			compatible = "espressif,esp32-adc"; /* in zephyr/dts/xtensa/espressif/esp32s2/esp32s2_common.dtsi:423 */
			reg = < 0x3f440028 0x64 >;          /* in zephyr/dts/xtensa/espressif/esp32s2/esp32s2_common.dtsi:424 */
			clocks = < &clock 0x1e >;           /* in zephyr/dts/xtensa/espressif/esp32s2/esp32s2_common.dtsi:425 */
			unit = < 0x2 >;                     /* in zephyr/dts/xtensa/espressif/esp32s2/esp32s2_common.dtsi:426 */
			channel-count = < 0xa >;            /* in zephyr/dts/xtensa/espressif/esp32s2/esp32s2_common.dtsi:427 */
			#io-channel-cells = < 0x1 >;        /* in zephyr/dts/xtensa/espressif/esp32s2/esp32s2_common.dtsi:428 */
			status = "disabled";                /* in zephyr/dts/xtensa/espressif/esp32s2/esp32s2_common.dtsi:429 */
		};

		/* node '/soc/can@3f42b000' defined in zephyr/dts/xtensa/espressif/esp32s2/esp32s2_common.dtsi:432 */
		twai: can@3f42b000 {
			compatible = "espressif,esp32-twai"; /* in zephyr/dts/xtensa/espressif/esp32s2/esp32s2_common.dtsi:433 */
			reg = < 0x3f42b000 0x1000 >;         /* in zephyr/dts/xtensa/espressif/esp32s2/esp32s2_common.dtsi:434 */
			interrupts = < 0x2f 0x0 0x0 >;       /* in zephyr/dts/xtensa/espressif/esp32s2/esp32s2_common.dtsi:435 */
			interrupt-parent = < &intc >;        /* in zephyr/dts/xtensa/espressif/esp32s2/esp32s2_common.dtsi:436 */
			clocks = < &clock 0x12 >;            /* in zephyr/dts/xtensa/espressif/esp32s2/esp32s2_common.dtsi:437 */
			status = "disabled";                 /* in zephyr/dts/xtensa/espressif/esp32s2/esp32s2_common.dtsi:438 */
		};

		/* node '/soc/sha@6003b000' defined in zephyr/dts/xtensa/espressif/esp32s2/esp32s2_common.dtsi:441 */
		sha: sha@6003b000 {
			compatible = "espressif,esp32-sha"; /* in zephyr/dts/xtensa/espressif/esp32s2/esp32s2_common.dtsi:442 */
			reg = < 0x6003b000 0x100 >;         /* in zephyr/dts/xtensa/espressif/esp32s2/esp32s2_common.dtsi:443 */
			clocks = < &clock 0x18 >;           /* in zephyr/dts/xtensa/espressif/esp32s2/esp32s2_common.dtsi:444 */
			status = "okay";                    /* in zephyr/dts/xtensa/espressif/esp32s2/esp32s2_common.dtsi:445 */
		};

		/* node '/soc/aes@6003a000' defined in zephyr/dts/xtensa/espressif/esp32s2/esp32s2_common.dtsi:448 */
		aes: aes@6003a000 {
			compatible = "espressif,esp32-aes"; /* in zephyr/dts/xtensa/espressif/esp32s2/esp32s2_common.dtsi:449 */
			reg = < 0x6003a000 0x1000 >;        /* in zephyr/dts/xtensa/espressif/esp32s2/esp32s2_common.dtsi:450 */
			clocks = < &clock 0x17 >;           /* in zephyr/dts/xtensa/espressif/esp32s2/esp32s2_common.dtsi:451 */
			status = "okay";                    /* in zephyr/dts/xtensa/espressif/esp32s2/esp32s2_common.dtsi:452 */
		};
	};

	/* node '/cpus' defined in zephyr/dts/xtensa/espressif/esp32s2/esp32s2_common.dtsi:30 */
	cpus {
		#address-cells = < 0x1 >; /* in zephyr/dts/xtensa/espressif/esp32s2/esp32s2_common.dtsi:31 */
		#size-cells = < 0x0 >;    /* in zephyr/dts/xtensa/espressif/esp32s2/esp32s2_common.dtsi:32 */

		/* node '/cpus/cpu@0' defined in zephyr/dts/xtensa/espressif/esp32s2/esp32s2_common.dtsi:34 */
		cpu0: cpu@0 {
			device_type = "cpu";                             /* in zephyr/dts/xtensa/espressif/esp32s2/esp32s2_common.dtsi:35 */
			compatible = "espressif,xtensa-lx7";             /* in zephyr/dts/xtensa/espressif/esp32s2/esp32s2_common.dtsi:36 */
			reg = < 0x0 >;                                   /* in zephyr/dts/xtensa/espressif/esp32s2/esp32s2_common.dtsi:37 */
			cpu-power-states = < &light_sleep &deep_sleep >; /* in zephyr/dts/xtensa/espressif/esp32s2/esp32s2_common.dtsi:38 */
			clock-source = < 0x1 >;                          /* in zephyr/dts/xtensa/espressif/esp32s2/esp32s2_common.dtsi:39 */
			clock-frequency = < 0xe4e1c00 >;                 /* in zephyr/dts/xtensa/espressif/esp32s2/esp32s2_common.dtsi:40 */
			xtal-freq = < 0x2625a00 >;                       /* in zephyr/dts/xtensa/espressif/esp32s2/esp32s2_common.dtsi:41 */
		};

		/* node '/cpus/power-states' defined in zephyr/dts/xtensa/espressif/esp32s2/esp32s2_common.dtsi:44 */
		power-states {

			/* node '/cpus/power-states/light_sleep' defined in zephyr/dts/xtensa/espressif/esp32s2/esp32s2_common.dtsi:45 */
			light_sleep: light_sleep {
				compatible = "zephyr,power-state"; /* in zephyr/dts/xtensa/espressif/esp32s2/esp32s2_common.dtsi:46 */
				power-state-name = "standby";      /* in zephyr/dts/xtensa/espressif/esp32s2/esp32s2_common.dtsi:47 */
				min-residency-us = < 0xc8 >;       /* in zephyr/dts/xtensa/espressif/esp32s2/esp32s2_common.dtsi:48 */
				exit-latency-us = < 0x3c >;        /* in zephyr/dts/xtensa/espressif/esp32s2/esp32s2_common.dtsi:49 */
				phandle = < 0x9 >;                 /* in zephyr/dts/xtensa/espressif/esp32s2/esp32s2_common.dtsi:38 */
			};

			/* node '/cpus/power-states/deep_sleep' defined in zephyr/dts/xtensa/espressif/esp32s2/esp32s2_common.dtsi:52 */
			deep_sleep: deep_sleep {
				compatible = "zephyr,power-state"; /* in zephyr/dts/xtensa/espressif/esp32s2/esp32s2_common.dtsi:53 */
				power-state-name = "soft-off";     /* in zephyr/dts/xtensa/espressif/esp32s2/esp32s2_common.dtsi:54 */
				min-residency-us = < 0x7d0 >;      /* in zephyr/dts/xtensa/espressif/esp32s2/esp32s2_common.dtsi:55 */
				exit-latency-us = < 0xd4 >;        /* in zephyr/dts/xtensa/espressif/esp32s2/esp32s2_common.dtsi:56 */
				phandle = < 0xa >;                 /* in zephyr/dts/xtensa/espressif/esp32s2/esp32s2_common.dtsi:38 */
			};
		};
	};

	/* node '/wifi' defined in zephyr/dts/xtensa/espressif/esp32s2/esp32s2_common.dtsi:61 */
	wifi: wifi {
		compatible = "espressif,esp32-wifi"; /* in zephyr/dts/xtensa/espressif/esp32s2/esp32s2_common.dtsi:62 */
		status = "okay";                     /* in zephyr/boards/espressif/esp32s2_devkitc/esp32s2_devkitc.dts:134 */
	};

	/* node '/esp32_bt_hci' defined in zephyr/dts/xtensa/espressif/esp32s2/esp32s2_common.dtsi:66 */
	esp32_bt_hci: esp32_bt_hci {
		compatible = "espressif,esp32-bt-hci"; /* in zephyr/dts/xtensa/espressif/esp32s2/esp32s2_common.dtsi:67 */
		status = "disabled";                   /* in zephyr/dts/xtensa/espressif/esp32s2/esp32s2_common.dtsi:68 */
	};

	/* node '/pin-controller' defined in zephyr/dts/xtensa/espressif/esp32s2/esp32s2_common.dtsi:71 */
	pinctrl: pin-controller {
		compatible = "espressif,esp32-pinctrl"; /* in zephyr/dts/xtensa/espressif/esp32s2/esp32s2_common.dtsi:72 */
		status = "okay";                        /* in zephyr/dts/xtensa/espressif/esp32s2/esp32s2_common.dtsi:73 */

		/* node '/pin-controller/uart0_default' defined in zephyr/boards/espressif/esp32s2_devkitc/esp32s2_devkitc-pinctrl.dtsi:12 */
		uart0_default: uart0_default {
			phandle = < 0x3 >; /* in zephyr/boards/espressif/esp32s2_devkitc/esp32s2_devkitc.dts:47 */

			/* node '/pin-controller/uart0_default/group1' defined in zephyr/boards/espressif/esp32s2_devkitc/esp32s2_devkitc-pinctrl.dtsi:13 */
			group1 {
				pinmux = < 0x77feb >; /* in zephyr/boards/espressif/esp32s2_devkitc/esp32s2_devkitc-pinctrl.dtsi:14 */
				output-high;          /* in zephyr/boards/espressif/esp32s2_devkitc/esp32s2_devkitc-pinctrl.dtsi:15 */
			};

			/* node '/pin-controller/uart0_default/group2' defined in zephyr/boards/espressif/esp32s2_devkitc/esp32s2_devkitc-pinctrl.dtsi:18 */
			group2 {
				pinmux = < 0xff83ac >; /* in zephyr/boards/espressif/esp32s2_devkitc/esp32s2_devkitc-pinctrl.dtsi:19 */
				bias-pull-up;          /* in zephyr/boards/espressif/esp32s2_devkitc/esp32s2_devkitc-pinctrl.dtsi:20 */
			};
		};

		/* node '/pin-controller/spim2_default' defined in zephyr/boards/espressif/esp32s2_devkitc/esp32s2_devkitc-pinctrl.dtsi:24 */
		spim2_default: spim2_default {
			phandle = < 0x7 >; /* in zephyr/boards/espressif/esp32s2_devkitc/esp32s2_devkitc.dts:113 */

			/* node '/pin-controller/spim2_default/group1' defined in zephyr/boards/espressif/esp32s2_devkitc/esp32s2_devkitc-pinctrl.dtsi:25 */
			group1 {
				pinmux = < 0xff9b4d >,
				         < 0x367fcc >,
				         < 0x3affca >; /* in zephyr/boards/espressif/esp32s2_devkitc/esp32s2_devkitc-pinctrl.dtsi:26 */
			};

			/* node '/pin-controller/spim2_default/group2' defined in zephyr/boards/espressif/esp32s2_devkitc/esp32s2_devkitc-pinctrl.dtsi:31 */
			group2 {
				pinmux = < 0x377fcb >; /* in zephyr/boards/espressif/esp32s2_devkitc/esp32s2_devkitc-pinctrl.dtsi:32 */
				output-low;            /* in zephyr/boards/espressif/esp32s2_devkitc/esp32s2_devkitc-pinctrl.dtsi:33 */
			};
		};

		/* node '/pin-controller/spim3_default' defined in zephyr/boards/espressif/esp32s2_devkitc/esp32s2_devkitc-pinctrl.dtsi:37 */
		spim3_default: spim3_default {
			phandle = < 0x8 >; /* in zephyr/boards/espressif/esp32s2_devkitc/esp32s2_devkitc.dts:121 */

			/* node '/pin-controller/spim3_default/group1' defined in zephyr/boards/espressif/esp32s2_devkitc/esp32s2_devkitc-pinctrl.dtsi:38 */
			group1 {
				pinmux = < 0xff9265 >,
				         < 0x247fe4 >,
				         < 0x267fe2 >; /* in zephyr/boards/espressif/esp32s2_devkitc/esp32s2_devkitc-pinctrl.dtsi:39 */
			};

			/* node '/pin-controller/spim3_default/group2' defined in zephyr/boards/espressif/esp32s2_devkitc/esp32s2_devkitc-pinctrl.dtsi:44 */
			group2 {
				pinmux = < 0x257fe3 >; /* in zephyr/boards/espressif/esp32s2_devkitc/esp32s2_devkitc-pinctrl.dtsi:45 */
				output-low;            /* in zephyr/boards/espressif/esp32s2_devkitc/esp32s2_devkitc-pinctrl.dtsi:46 */
			};
		};

		/* node '/pin-controller/i2c0_default' defined in zephyr/boards/espressif/esp32s2_devkitc/esp32s2_devkitc-pinctrl.dtsi:50 */
		i2c0_default: i2c0_default {
			phandle = < 0x4 >; /* in zephyr/boards/espressif/esp32s2_devkitc/esp32s2_devkitc.dts:90 */

			/* node '/pin-controller/i2c0_default/group1' defined in zephyr/boards/espressif/esp32s2_devkitc/esp32s2_devkitc-pinctrl.dtsi:51 */
			group1 {
				pinmux = < 0xf0788 >,
				         < 0xe8749 >; /* in zephyr/boards/espressif/esp32s2_devkitc/esp32s2_devkitc-pinctrl.dtsi:52 */
				bias-pull-up;         /* in zephyr/boards/espressif/esp32s2_devkitc/esp32s2_devkitc-pinctrl.dtsi:54 */
				drive-open-drain;     /* in zephyr/boards/espressif/esp32s2_devkitc/esp32s2_devkitc-pinctrl.dtsi:55 */
				output-high;          /* in zephyr/boards/espressif/esp32s2_devkitc/esp32s2_devkitc-pinctrl.dtsi:56 */
			};
		};

		/* node '/pin-controller/i2c1_default' defined in zephyr/boards/espressif/esp32s2_devkitc/esp32s2_devkitc-pinctrl.dtsi:60 */
		i2c1_default: i2c1_default {
			phandle = < 0x5 >; /* in zephyr/boards/espressif/esp32s2_devkitc/esp32s2_devkitc.dts:96 */

			/* node '/pin-controller/i2c1_default/group1' defined in zephyr/boards/espressif/esp32s2_devkitc/esp32s2_devkitc-pinctrl.dtsi:61 */
			group1 {
				pinmux = < 0x301803 >,
				         < 0x2f97c4 >; /* in zephyr/boards/espressif/esp32s2_devkitc/esp32s2_devkitc-pinctrl.dtsi:62 */
				bias-pull-up;          /* in zephyr/boards/espressif/esp32s2_devkitc/esp32s2_devkitc-pinctrl.dtsi:64 */
				drive-open-drain;      /* in zephyr/boards/espressif/esp32s2_devkitc/esp32s2_devkitc-pinctrl.dtsi:65 */
				output-high;           /* in zephyr/boards/espressif/esp32s2_devkitc/esp32s2_devkitc-pinctrl.dtsi:66 */
			};
		};

		/* node '/pin-controller/i2s0_default' defined in zephyr/boards/espressif/esp32s2_devkitc/esp32s2_devkitc-pinctrl.dtsi:70 */
		i2s0_default: i2s0_default {
			phandle = < 0x6 >; /* in zephyr/boards/espressif/esp32s2_devkitc/esp32s2_devkitc.dts:101 */

			/* node '/pin-controller/i2s0_default/group1' defined in zephyr/boards/espressif/esp32s2_devkitc/esp32s2_devkitc-pinctrl.dtsi:71 */
			group1 {
				pinmux = < 0x7dffc4 >,
				         < 0xc8645 >,
				         < 0xb85c6 >,
				         < 0x537fd2 >,
				         < 0xffa791 >; /* in zephyr/boards/espressif/esp32s2_devkitc/esp32s2_devkitc-pinctrl.dtsi:72 */
			};
		};
	};

	/* node '/clock' defined in zephyr/dts/xtensa/espressif/esp32s2/esp32s2_common.dtsi:76 */
	clock: clock {
		compatible = "espressif,esp32-clock"; /* in zephyr/dts/xtensa/espressif/esp32s2/esp32s2_common.dtsi:77 */
		fast-clk-src = < 0x0 >;               /* in zephyr/dts/xtensa/espressif/esp32s2/esp32s2_common.dtsi:78 */
		slow-clk-src = < 0x0 >;               /* in zephyr/dts/xtensa/espressif/esp32s2/esp32s2_common.dtsi:79 */
		#clock-cells = < 0x1 >;               /* in zephyr/dts/xtensa/espressif/esp32s2/esp32s2_common.dtsi:80 */
		status = "okay";                      /* in zephyr/dts/xtensa/espressif/esp32s2/esp32s2_common.dtsi:81 */
		phandle = < 0x1 >;                    /* in zephyr/dts/xtensa/espressif/esp32s2/esp32s2_common.dtsi:149 */
	};

	/* node '/gpio_keys' defined in zephyr/boards/espressif/esp32s2_devkitc/esp32s2_devkitc.dts:33 */
	gpio_keys {
		compatible = "gpio-keys"; /* in zephyr/boards/espressif/esp32s2_devkitc/esp32s2_devkitc.dts:34 */

		/* node '/gpio_keys/user_button' defined in zephyr/boards/espressif/esp32s2_devkitc/esp32s2_devkitc.dts:36 */
		user_button: user_button {
			label = "BOOT";              /* in zephyr/boards/espressif/esp32s2_devkitc/esp32s2_devkitc.dts:37 */
			gpios = < &gpio0 0x0 0x11 >; /* in zephyr/boards/espressif/esp32s2_devkitc/esp32s2_devkitc.dts:38 */
			zephyr,code = < 0xb >;       /* in zephyr/boards/espressif/esp32s2_devkitc/esp32s2_devkitc.dts:39 */
		};
	};
};
